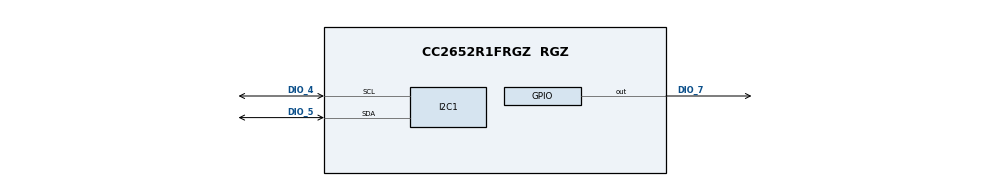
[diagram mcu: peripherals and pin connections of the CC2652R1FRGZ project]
/**
 * @cliArgs --device "CC2652R1FRGZ" --package "RGZ" --part "Default" --product "simplelink_cc13x2_26x2_sdk@4.30.00.54"
 * @versions {"data":"2020090214","timestamp":"2020090214","tool":"1.6.0+1543","templates":"2020090214"}
 */

/**
 * Import the modules used in this configuration.
 */
const CCFG     = scripting.addModule("/ti/devices/CCFG");
const custom   = scripting.addModule("/ti/devices/radioconfig/custom");
const rfdesign = scripting.addModule("/ti/devices/radioconfig/rfdesign");
const GPIO     = scripting.addModule("/ti/drivers/GPIO");
const GPIO1    = GPIO.addInstance();
const I2C      = scripting.addModule("/ti/drivers/I2C", {}, false);
const I2C1     = I2C.addInstance();
const RF       = scripting.addModule("/ti/drivers/RF");
const RTOS     = scripting.addModule("/ti/drivers/RTOS");

/**
 * Write custom configuration values to the imported modules.
 */
CCFG.enableBootloader         = true;
CCFG.enableBootloaderBackdoor = true;
CCFG.dioBootloaderBackdoor    = 13;
CCFG.levelBootloaderBackdoor  = "Active low";
CCFG.ccfgTemplate.$name       = "ti_devices_CCFGTemplate0";

custom.prop2                                               = ["custom2400"];
custom.radioConfigcustom2400.phyType2400                   = "2gfsk100kbps";
custom.radioConfigcustom2400.$name                         = "RF_Custom_Setting";
custom.radioConfigcustom2400.codeExportConfig.$name        = "ti_devices_radioconfig_code_export_param0";
custom.radioConfigcustom2400.codeExportConfig.symGenMethod = "Legacy";

GPIO1.mode              = "Output";
GPIO1.$name             = "CONFIG_GPIO_GLED";
GPIO1.gpioPin.$assign   = "DIO_7";
GPIO1.pinInstance.$name = "CONFIG_PIN_GLED";

I2C1.$name                = "CONFIG_I2C_0";
I2C1.i2c.$assign          = "I2C0";
I2C1.i2c.sdaPin.$assign   = "DIO_5";
I2C1.i2c.sclPin.$assign   = "DIO_4";
I2C1.sdaPinInstance.$name = "CONFIG_PIN_0";
I2C1.clkPinInstance.$name = "CONFIG_PIN_1";
